# STM32G061 register map
File version: 1.4
CPU: CM0 r0p1, little endian, MPU, no FPU, 2 interrupt priority bits
Registers are 32-bit, read-write, reset 0x0 unless marked. A register's access mark holds for its fields unless they carry their own. Offsets are from the block's base; [hi:lo] are bit positions.

## RNG — Random number generator
Base 0x40025000
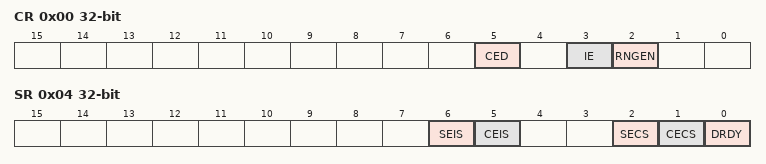
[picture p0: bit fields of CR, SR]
0x00 CR — control register
  [5] CED — Clock error detection The clock error detection cannot be enabled nor disabled on-the-fly when the RNG is enabled, i.e. to enable or disable CED the RNG must be disabled.
    0=Enabled (Clock error detection is enabled); 1=Disabled (Clock error detection is disabled)
  [3] IE — Interrupt Enable
    0=Disabled (RNG interrupt is disabled); 1=Enabled (RNG interrupt is enabled)
  [2] RNGEN — True random number generator enable
    0=Disabled (Random number generator is disabled); 1=Enabled (Random number generator is enabled)
0x04 SR access per field — status register
  [6] SEIS rw write-0-clears — Seed error interrupt status This bit is set at the same time as SECS. It is cleared by writing 0. Writing 1 has no effect. An interrupt is pending if IE = 1 in the RNG_CR register.
    on write: 0=Clear flag | on read: 0=No faulty sequence detected; 1=Fault (At least one faulty sequence has been detected. See **SECS** bit description for details. An interrupt is pending if IE = 1 in the RNG_CR register.)
  [5] CEIS rw write-0-clears — Clock error interrupt status This bit is set at the same time as CECS. It is cleared by writing 0. Writing 1 has no effect. An interrupt is pending if IE = 1 in the RNG_CR register.
    on write: 0=Clear flag | on read: 0=Correct (The RNG clock is correct); 1=Slow (The RNG has been detected too slow An interrupt is pending if IE = 1 in the RNG_CR register)
  [2] SECS ro — Seed error current status One of the noise source has provided more than 64 consecutive bits at a constant value ('0' or '1'), or more than 32 consecutive occurrence of two bit patterns ('01' or '10') Both noise sources have delivered more than 32 consecutive bits at a constant value ('0' or '1'), or more than 16 consecutive occurrence of two bit patterns ('01' or '10')
    0=No faulty sequence has currently been detected. If the SEIS bit is set, this means that a faulty sequence was detected and the situation has been recovered.; 1=Fault (At least one faulty sequence has been detected - see ref manual for details)
  [1] CECS ro — Clock error current status Note: CECS bit is valid only if the CED bit in the RNG_CR register is set to 0.
    0=Correct (The RNG clock is correct. If the CEIS bit is set, this means that a slow clock was detected and the situation has been recovered.); 1=Slow (The RNG clock is too slow)
  [0] DRDY ro — Data Ready Once the output buffer becomes empty (after reading the RNG_DR register), this bit returns to 0 until a new random value is generated. Note: The DRDY bit can rise when the peripheral is disabled (RNGEN=0 in the RNG_CR register). If IE=1 in the RNG_CR register, an interrupt is generated when DRDY=1.
    0=Invalid (The RNG_DR register is not yet valid, no random data is available); 1=Valid (The RNG_DR register contains valid random data. Once the RNG_DR register has been read, this bit returns to 0 until a new random value is generated.)
0x08 DR ro — RNG data register
  [31:0] RNDATA — Random data 32-bit random data which are valid when DRDY=1. When DRDY=0 RNDATA value is zero. It is recommended to always verify that RNG_DR is different from zero. Because when it is the case a seed error occurred between RNG_SR polling and RND_DR output reading (rare event).

## TIM6 — Basic timers
Base 0x40001000
Same registers: TIM7 0x40001400
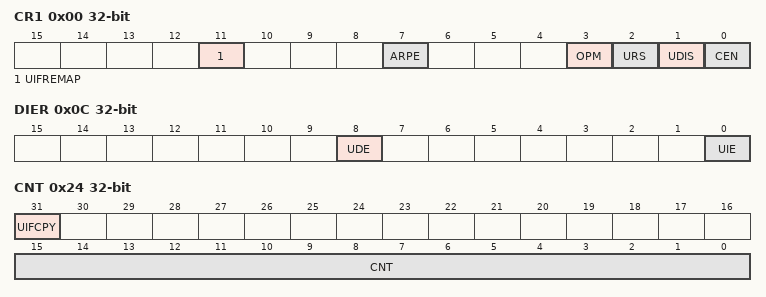
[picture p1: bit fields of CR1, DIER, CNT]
0x00 CR1 — control register 1
  [11] UIFREMAP — UIF status bit remapping
  [7] ARPE — Auto-reload preload enable
    0=Disabled (TIMx_APRR register is not buffered); 1=Enabled (TIMx_APRR register is buffered)
  [3] OPM — One-pulse mode
    0=Disabled (Counter is not stopped at update event); 1=Enabled (Counter stops counting at the next update event (clearing the CEN bit))
  [2] URS — Update request source This bit is set and cleared by software to select the UEV event sources. Counter overflow/underflow Setting the UG bit Update generation through the slave mode controller
    0=AnyEvent (Any of counter overflow/underflow, setting UG, or update through slave mode, generates an update interrupt or DMA request); 1=CounterOnly (Only counter overflow/underflow generates an update interrupt or DMA request)
  [1] UDIS — Update disable This bit is set and cleared by software to enable/disable UEV event generation. Counter overflow/underflow Setting the UG bit Update generation through the slave mode controller Buffered registers are then loaded with their preload values.
    0=Enabled (Update event enabled); 1=Disabled (Update event disabled)
  [0] CEN — Counter enable Note: Gated mode can work only if the CEN bit has been previously set by software. However trigger mode can set the CEN bit automatically by hardware. CEN is cleared automatically in one-pulse mode, when an update event occurs.
    0=Disabled (Counter disabled); 1=Enabled (Counter enabled)
0x04 CR2 — control register 2
  [6:4] MMS — Master mode selection These bits are used to select the information to be sent in master mode to slave timers for synchronization (TRGO). The combination is as follows: When the Counter Enable signal is controlled by the trigger input, there is a delay on TRGO, except if the master/slave mode is selected (see the MSM bit description in the TIMx_SMCR register). Note: The clock of the slave timer or ADC must be enabled prior to receive events from the master timer, and must not be changed on-the-fly while triggers are received from the master timer.
    0=Reset (Use UG bit from TIMx_EGR register); 1=Enable (Use CNT bit from TIMx_CEN register); 2=Update (Use the update event)
0x0C DIER — DMA/Interrupt enable register
  [8] UDE — Update DMA request enable
    0=Disabled (Update DMA request disabled); 1=Enabled (Update DMA request enabled)
  [0] UIE — Update interrupt enable
    0=Disabled (Update interrupt disabled); 1=Enabled (Update interrupt enabled)
0x10 SR — status register
  [0] UIF write-0-clears — Update interrupt flag This bit is set by hardware on an update event. It is cleared by software. At overflow or underflow regarding the repetition counter value and if UDIS = 0 in the TIMx_CR1 register. When CNT is reinitialized by software using the UG bit in the TIMx_EGR register, if URS=0 and UDIS=0 in the TIMx_CR1 register.
    on read: 0=NoUpdateOccurred; 1=UpdatePending (Update interrupt pending) | on write: 0=Clear flag
0x14 EGR wo — event generation register
  [0] UG — Update generation This bit can be set by software, it is automatically cleared by hardware.
    1=Update (Re-initializes the timer counter and generates an update of the registers.)
0x24 CNT — counter
  [31] UIFCPY ro — UIF Copy This bit is a read-only copy of the UIF bit of the TIMx_ISR register. If the UIFREMAP bit in TIMx_CR1 is reset, bit 31 is reserved and read as 0.
  [15:0] CNT — Counter value
0x28 PSC — prescaler
  [15:0] PSC — Prescaler value
0x2C ARR reset 0xFFFF — auto-reload register
  [15:0] ARR — Prescaler value

## VREFBUF — System configuration controller
Base 0x40010030
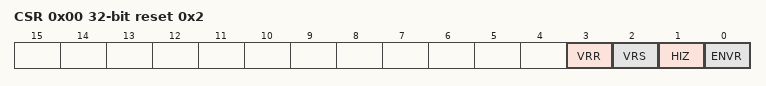
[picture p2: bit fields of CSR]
0x00 CSR access per field reset 0x2 — VREFBUF control and status register
  [3] VRR ro — Voltage reference buffer ready
  [2] VRS rw — Voltage reference scale This bit selects the value generated by the voltage reference buffer.
  [1] HIZ rw — High impedance mode This bit controls the analog switch to connect or not the VREF+ pin. Refer to for the mode descriptions depending on ENVR bit configuration.
  [0] ENVR rw — Voltage reference buffer mode enable This bit is used to enable the voltage reference buffer mode.
0x04 CCR — VREFBUF calibration control register
  [5:0] TRIM — Trimming code These bits are automatically initialized after reset with the trimming value stored in the Flash memory during the production test. Writing into these bits allows the tuning of the internal reference buffer voltage.

## WWDG — System window watchdog
Base 0x40002C00
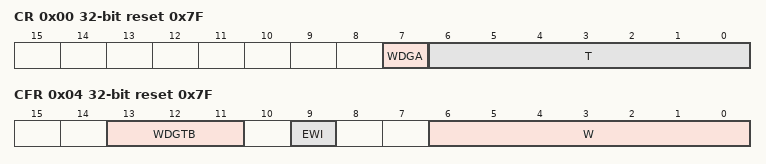
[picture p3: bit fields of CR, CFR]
0x00 CR reset 0x7F — Control register
  [7] WDGA — Activation bit This bit is set by software and only cleared by hardware after a reset. When WDGA=1, the watchdog can generate a reset.
    0=Disabled (Watchdog disabled); 1=Enabled (Watchdog enabled)
  [6:0] T — 7-bit counter (MSB to LSB) These bits contain the value of the watchdog counter, decremented every (4096 x 2WDGTB[1:0]) PCLK cycles. A reset is produced when it is decremented from 0x40 to 0x3F (T6 becomes cleared).
0x04 CFR reset 0x7F — Configuration register
  [13:11] WDGTB — Timer base The timebase of the prescaler can be modified as follows:
    0=Div1 (Counter clock (PCLK1 div 4096) div 1); 1=Div2 (Counter clock (PCLK1 div 4096) div 2); 2=Div4 (Counter clock (PCLK1 div 4096) div 4); 3=Div8 (Counter clock (PCLK1 div 4096) div 8); 4=Div16 (Counter clock (PCLK1 div 4096) div 16); 5=Div32 (Counter clock (PCLK1 div 4096) div 32); 6=Div64 (Counter clock (PCLK1 div 4096) div 64); 7=Div128 (Counter clock (PCLK1 div 4096) div 128)
  [9] EWI — Early wakeup interrupt When set, an interrupt occurs whenever the counter reaches the value 0x40. This interrupt is only cleared by hardware after a reset.
    on write: 1=Enable (interrupt occurs whenever the counter reaches the value 0x40)
  [6:0] W — 7-bit window value These bits contain the window value to be compared with the down-counter.
0x08 SR — Status register
  [0] EWIF write-0-clears — Early wakeup interrupt flag
    on read: 0=Finished (The EWI Interrupt Service Routine has been serviced); 1=Pending (The EWI Interrupt Service Routine has been triggered) | on write: 0=Finished (The EWI Interrupt Service Routine has been serviced)
